# SIM3C167_B register map
File version: 1
CPU: 
Registers are 32-bit, read-write, reset 0x0 unless marked. A register's access mark holds for its fields unless they carry their own. Offsets are from the block's base; [hi:lo] are bit positions; <NAME> marks a mode.

## LPOSC_0
Base 0x40041000
0x00 OSCVAL reset 0x8 — Low Power Oscillator Output Value
  [3:0] OSCVAL ro — Low Power Oscillator Output Value.

## PBSTD_0
Base 0x4002A0A0
Same registers: PBSTD_1 0x4002A140
0x00 PB reset 0xFFFF — Output Latch
  [15:0] PB — Output Latch.
0x10 PBPIN — Pin Value
  [15:0] PBPIN ro — Pin Value.
0x20 PBMDSEL reset 0xFFFF — Mode Select
  [15:0] PBMDSEL — Mode Select.
0x30 PBSKIPEN — Crossbar Pin Skip Enable
  [15:0] PBSKIPEN — Crossbar Pin Skip Enable.
0x40 PBOUTMD — Output Mode
  [15:0] PBOUTMD — Output Mode.
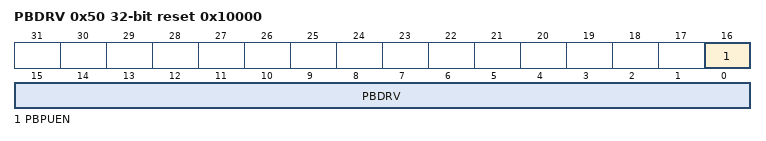
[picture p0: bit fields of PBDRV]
0x50 PBDRV reset 0x10000 — Drive Strength
  [16] PBPUEN — Port Bank Weak Pull-up Enable.
    0=DISABLED (Disable weak pull-ups for this port.); 1=ENABLED (Enable weak pull-ups for this port.)
  [15:0] PBDRV — Drive Strength.
0x60 PM — Port Match Value
  [15:0] PM — Port Match Value.
0x70 PMEN — Port Match Enable
  [15:0] PMEN — Port Match Enable.

## PBSTD_2
Base 0x4002A1E0
Registers as PBSTD_0; these are added or differ:
0x80 PBLOCK — Lock Control
  [15:0] PBLOCK — Port Bank Lock.
0x90 PBPGEN — Pulse Generator Pin Enable
  [15:0] PBPGEN — Pulse Generator Pin Enable.
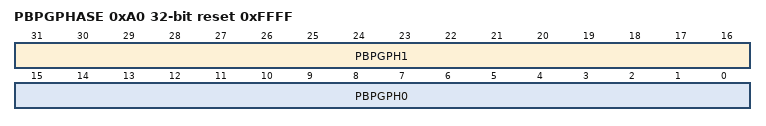
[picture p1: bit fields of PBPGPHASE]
0xA0 PBPGPHASE reset 0xFFFF — Pulse Generator Phase
  [31:16] PBPGPH1 — Pulse Generator Phase 1.
  [15:0] PBPGPH0 — Pulse Generator Phase 0.

## PBSTD_3
Base 0x4002A320
Registers as PBSTD_2, without PBPGEN, PBPGPHASE.

## RSTSRC_0
Base 0x4002D060
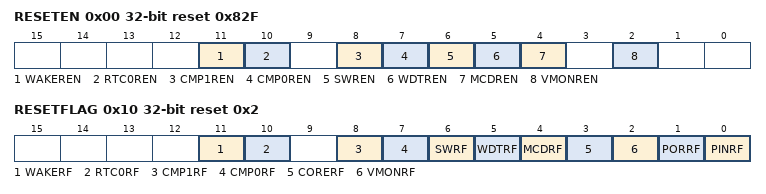
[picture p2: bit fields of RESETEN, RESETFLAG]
0x00 RESETEN reset 0x82F — System Reset Source Enable
  [11] WAKEREN — PMU Wakeup Reset Enable.
    1=ENABLED (Enable the PMU Wakeup event as a reset source.)
  [10] RTC0REN — RTC0 Reset Enable.
    0=DISABLED (Disable the RTC0 event as a reset source.); 1=ENABLED (Enable the RTC0 event as a reset source.)
  [8] CMP1REN — Comparator 1 Reset Enable.
    0=DISABLED (Disable the Comparator 1 event as a reset source.); 1=ENABLED (Enable the Comparator 1 event as a reset source.)
  [7] CMP0REN — Comparator 0 Reset Enable.
    0=DISABLED (Disable the Comparator 0 event as a reset source.); 1=ENABLED (Enable the Comparator 0 event as a reset source.)
  [6] SWREN — Software Reset.
    0=DISABLED (Do not generate a Software Reset.); 1=ENABLED (Generate a Software Reset.)
  [5] WDTREN — Watchdog Timer Reset Enable.
    0=DISABLED (Disable the Watchdog Timer event as a reset source.); 1=ENABLED (Enable the Watchdog Timer event as a reset source.)
  [4] MCDREN — Missing Clock Detector Reset Enable.
    0=DISABLED (Disable the Missing Clock Detector event as a reset source.); 1=ENABLED (Enable the Missing Clock Detector event as a reset source.)
  [2] VMONREN — Voltage Supply Monitor VDD Reset Enable.
    0=DISABLED (Disable the Voltage Supply Monitor VDD event as a reset source.); 1=ENABLED (Enable the Voltage Supply Monitor VDD event as a reset source.)
0x10 RESETFLAG reset 0x2 — System Reset Flags
  [11] WAKERF ro — PMU Wakeup Reset Flag.
    0=NOT_SET (A PMU Wakeup event did not cause the last system reset.); 1=SET (A PMU Wakeup event caused the last system reset.)
  [10] RTC0RF ro — RTC0 Reset Flag.
    0=NOT_SET (An RTC0 event did not cause the last system reset.); 1=SET (An RTC0 event caused the last system reset.)
  [8] CMP1RF ro — Comparator 1 Reset Flag.
    0=NOT_SET (A Comparator 1 event did not cause the last system reset.); 1=SET (A Comparator 1 event caused the last system reset.)
  [7] CMP0RF ro — Comparator 0 Reset Flag.
    0=NOT_SET (A Comparator 0 event did not cause the last system reset.); 1=SET (A Comparator 0 event caused the last system reset.)
  [6] SWRF ro — Software Reset Flag.
    0=NOT_SET (A Software Reset event did not cause the last system reset.); 1=SET (A Software Reset event caused the last system reset.)
  [5] WDTRF ro — Watchdog Timer Reset Flag.
    0=NOT_SET (A Watchdog Timer event did not cause the last system reset.); 1=SET (A Watchdog Timer event caused the last system reset.)
  [4] MCDRF ro — Missing Clock Detector Reset Flag.
    0=NOT_SET (A Missing Clock Detector event did not cause the last system reset.); 1=SET (A Missing Clock Detector event caused the last system reset.)
  [3] CORERF ro — Core Reset Flag.
    0=NOT_SET (A Core Reset event did not cause the last system reset.); 1=SET (A Core Reset event caused the last system reset.)
  [2] VMONRF ro — Voltage Supply Monitor VDD Reset Flag.
    0=NOT_SET (A Voltage Supply Monitor VDD Reset event did not cause the last system reset.); 1=SET (A Voltage Supply Monitor VDD Reset event caused the last system reset.)
  [1] PORRF ro — Power-On Reset Flag.
    0=NOT_SET (A Power-On Reset event did not cause the last system reset.); 1=SET (A Power-On Reset event caused the last system reset.)
  [0] PINRF ro — Pin Reset Flag.
    0=NOT_SET (A /RESET pin event did not cause the last system reset.); 1=SET (A /RESET pin event caused the last system reset.)
0x20 CONFIG — Configuration Options
  [0] PMSEL — Power Mode Select.
    0=PM9_DIS (Power Mode < PM9.); 1=PM9_EN (Power Mode = PM9.)
